# STM32MP23_CM33 register map
File version: 1.2
CPU: CM33 r0p1, little endian, MPU, FPU, vendor SysTick, 8 interrupt priority bits
Registers are 32-bit, read-write, reset 0x0 unless marked. A register's access mark holds for its fields unless they carry their own. Offsets are from the block's base; [hi:lo] are bit positions; {n}, {i} and the like mark numbered series; 'fields as' and 'values as' point back to an identical list.

## DSI (part 2 of 2) — DSI address block description
Base 0x48000000
Same registers: DSI_S 0x58000000
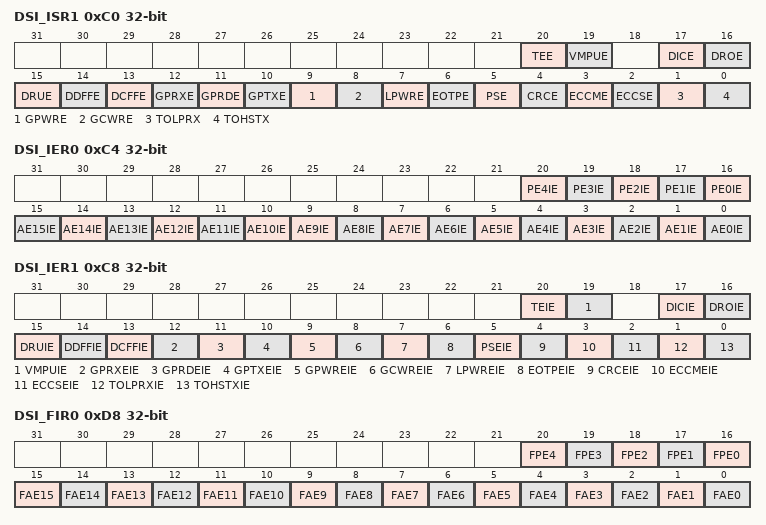
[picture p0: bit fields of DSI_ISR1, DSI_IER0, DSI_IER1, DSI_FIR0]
0xC0 DSI_ISR1 ro — DSI Host interrupt and status register 1
  [20] TEE — Tear effect error Indicates that tear_request has occurred, but tear effect is not active in DSI host and device.
  [19] VMPUE — Video mode underflow error Indicates that an underflow has occurred when reading payload to build DSI packet for video mode.
  [17] DICE — DBI illegal command error Indicates that an attempt to write an illegal command on the DBI interface is made and the controller is blocked by transmission.
  [16] DROE — DBI read overflow error Indicates that during a DBI read back packet, the payload FIFO becomes full and the received data is corrupted.
  [15] DRUE — DCS read underflow error Indicates that during a DCS read data, the payload FIFO goes empty and the data sent to the interface is corrupted.
  [14] DDFFE — DBI data FIFO full error Indicates that the system tried to write the payload data through the DBI interface and the FIFO is full. Therefore, the command is not written.
  [13] DCFFE — DBI command FIFO full error Indicates that the system tried to write a command through the DBI but the command FIFO is full. Therefore, the command is not written.
  [12] GPRXE — Generic payload receive error Indicates that during a generic interface packet read back, the payload FIFO becomes full and the received data is corrupted.
  [11] GPRDE — Generic payload read error Indicates that during a DCS read data, the payload FIFO becomes empty and the data sent to the interface is corrupted.
  [10] GPTXE — Generic payload transmit error Indicates that during a generic interface packet build, the payload FIFO becomes empty and corrupt data is sent.
  [9] GPWRE — Generic payload write error Indicates that the system tried to write a payload data through the generic interface and the FIFO is full. Therefore, the payload is not written.
  [8] GCWRE — Generic command write error Indicates that the system tried to write a command through the generic interface and the FIFO is full. Therefore, the command is not written.
  [7] LPWRE — LTDC payload write error Indicates that during a DPI pixel line storage, the payload FIFO becomes full and the data stored is corrupted.
  [6] EOTPE — EoTp error Indicates that the EoTp packet is not received at the end of the incoming peripheral transmission.
  [5] PSE — Packet size error Indicates that the packet size error is detected during the packet reception.
  [4] CRCE — CRC error Indicates that the CRC error is detected in the received packet payload.
  [3] ECCME — ECC multi-bit error Indicates that the ECC multiple error is detected in a received packet.
  [2] ECCSE — ECC single-bit error Indicates that the ECC single error is detected and corrected in a received packet.
  [1] TOLPRX — Timeout low-power reception Indicates that the low-power reception timeout counter reached the end and contention is detected.
  [0] TOHSTX — Timeout high-speed transmission Indicates that the high-speed transmission timeout counter reached the end and contention is detected.
0xC4 DSI_IER0 — DSI Host interrupt enable register 0
  [20] PE4IE — PHY error 4 interrupt enable Enables the interrupt generation on PHY error 4.
    0=Interrupt on PHY error 4 disabled; 1=Interrupt on PHY error 4 enabled
  [19] PE3IE — PHY error 3 interrupt enable Enables the interrupt generation on PHY error 4.
    0=Interrupt on PHY error 3 disabled; 1=Interrupt on PHY error 3 enabled
  [18] PE2IE — PHY error 2 interrupt enable Enables the interrupt generation on PHY error 2.
    0=Interrupt on PHY error 2 disabled; 1=Interrupt on PHY error 2 enabled
  [17] PE1IE — PHY error 1 interrupt enable Enables the interrupt generation on PHY error 1.
    0=Interrupt on PHY error 1 disabled; 1=Interrupt on PHY error 1 enabled
  [16] PE0IE — PHY error 0 interrupt enable Enables the interrupt generation on PHY error 0.
    0=Interrupt on PHY error 0 disabled; 1=Interrupt on PHY error 0 enabled
  [n] AE{n}IE (n=11..15) — Acknowledge error {n} interrupt enable Enables the interrupt generation on acknowledge error {n}.
    0=Interrupt on acknowledge error {n} disabled; 1=Interrupt on acknowledge error {n} enabled
  [10] AE10IE — Acknowledge error 10 interrupt enable Enables the interrupt generation on acknowledge error 10.
    0=Interrupt on acknowledge error 10 disabled; 1=Interrupt on acknowledge error 10 enable
  [n] AE{n}IE (n=0..9) — Acknowledge error {n} interrupt enable Enables the interrupt generation on acknowledge error {n}.
    values as AE11IE
0xC8 DSI_IER1 — DSI Host interrupt enable register 1
  [all] fields
    0=Interrupt disabled; 1=Interrupt enabled
  [20] TEIE ro — Tear effect error interrupt enable Enables the interrupt generation on tear effect error.
  [19] VMPUIE ro — Video mode underflow error interrupt enable Enables the interrupt generation on video mode underflow error.
  [17] DICIE ro — DBI illegal command error interrupt enable Enables the interrupt generation on DBI illegal command error.
  [16] DROIE ro — DBI read overflow error interrupt enable Enables the interrupt generation on DBI read overflow error.
  [15] DRUIE ro — DCS read underflow error interrupt enable Enables the interrupt generation on DCS read underflow error.
  [14] DDFFIE ro — DBI data FIFO full error interrupt enable Enables the interrupt generation on DBI data FIFO full error.
  [13] DCFFIE ro — DBI command FIFO full error interrupt enable Enables the interrupt generation on DBI command FIFO full error.
  [12] GPRXEIE — Generic payload receive error interrupt enable Enables the interrupt generation on generic payload receive error.
  [11] GPRDEIE — Generic payload read error interrupt enable Enables the interrupt generation on generic payload read error.
  [10] GPTXEIE — Generic payload transmit error interrupt enable Enables the interrupt generation on generic payload transmit error.
  [9] GPWREIE — Generic payload write error interrupt enable Enables the interrupt generation on generic payload write error.
  [8] GCWREIE — Generic command write error interrupt enable Enables the interrupt generation on generic command write error.
  [7] LPWREIE — LTDC payload write error interrupt enable Enables the interrupt generation on LTDC payload write error.
  [6] EOTPEIE — EoTp error interrupt enable Enables the interrupt generation on EoTp error.
  [5] PSEIE — Packet size error interrupt enable Enables the interrupt generation on packet size error.
  [4] CRCEIE — CRC error interrupt enable Enables the interrupt generation on CRC error.
  [3] ECCMEIE — ECC multi-bit error interrupt enable Enables the interrupt generation on ECC multi-bit error.
  [2] ECCSEIE — ECC single-bit error interrupt enable Enables the interrupt generation on ECC single-bit error.
  [1] TOLPRXIE — Timeout low-power reception interrupt enable Enables the interrupt generation on timeout low-power reception.
  [0] TOHSTXIE — Timeout high-speed transmission interrupt enable Enables the interrupt generation on timeout high-speed transmission.
0xCC DSI_PCCR — DSI Host PHY calibration control register
  [0] CSEN — Calibration start for the high-speed skew of the D-PHY:
    0=Calibration disabled; 1=Calibration enabled
0xD8 DSI_FIR0 wo — DSI Host force interrupt register 0
  [n+16] FPE{n} (n=0..4) — Force PHY error {n} Writing 1 to this bit forces a PHY error {n}.
  [n] FAE{n} (n=0..15) — Force acknowledge error {n} Writing 1 to this bit forces an acknowledge error {n}.
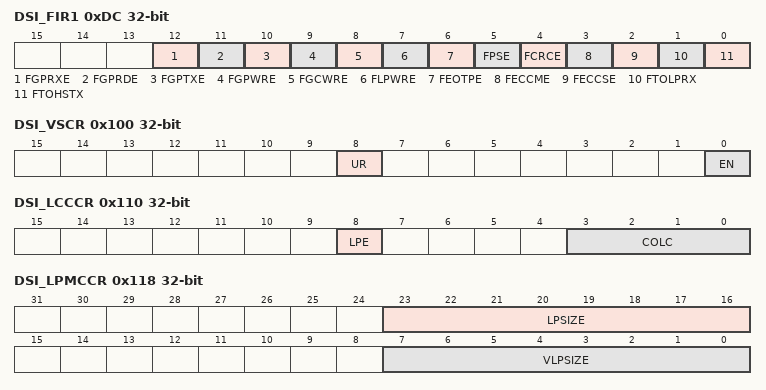
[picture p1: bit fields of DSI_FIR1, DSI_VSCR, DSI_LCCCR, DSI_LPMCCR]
0xDC DSI_FIR1 wo — DSI Host force interrupt register 1
  [12] FGPRXE — Force generic payload receive error Writing 1 to this bit forces a generic payload receive error.
  [11] FGPRDE — Force generic payload read error Writing 1 to this bit forces a generic payload read error.
  [10] FGPTXE — Force generic payload transmit error Writing 1 to this bit forces a generic payload transmit error.
  [9] FGPWRE — Force generic payload write error Writing 1 to this bit forces a generic payload write error.
  [8] FGCWRE — Force generic command write error Writing 1 to this bit forces a generic command write error.
  [7] FLPWRE — Force LTDC payload write error Writing 1 to this bit forces a LTDC payload write error.
  [6] FEOTPE — Force EoTp error Writing 1 to this bit forces a EoTp error.
  [5] FPSE — Force packet size error Writing 1 to this bit forces a packet size error.
  [4] FCRCE — Force CRC error Writing 1 to this bit forces a CRC error.
  [3] FECCME — Force ECC multi-bit error Writing 1 to this bit forces a ECC multi-bit error.
  [2] FECCSE — Force ECC single-bit error Writing 1 to this bit forces a ECC single-bit error.
  [1] FTOLPRX — Force timeout low-power reception Writing 1 to this bit forces a timeout low-power reception.
  [0] FTOHSTX — Force timeout high-speed transmission Writing 1 to this bit forces a timeout high-speed transmission.
0xF4 DSI_DLTRCR — DSI Host data lane timer read configuration register
  [14:0] MRD_TIME — Maximum read time This field configures the maximum time required to perform a read command in lane byte clock cycles. This register can only be modified when no read command is in progress.
0x100 DSI_VSCR — DSI Host video shadow control register
  [8] UR — Update register When set to 1, the LTDC registers are copied to the auxiliary registers. After copying, this bit is auto cleared.
    0=No update requested; 1=Register update requested
  [0] EN — Enable When set to 1, DSI Host LTDC interface receives the active configuration from the auxiliary registers. When this bit is set along with the UR bit, the auxiliary registers are automatically updated.
    0=Register update is disabled; 1=Register update is enabled
0x10C DSI_LCVCIDR — DSI Host LTDC current VCID register
  [1:0] VCID — Virtual channel ID This field returns the virtual channel ID for the LTDC interface.
0x110 DSI_LCCCR ro — DSI Host LTDC current color coding register
  [8] LPE — Loosely packed enable This bit returns the current state of the loosely packed variant to 18-bit configurations.
    0=Loosely packed variant disabled; 1=Loosely packed variant enabled
  [3:0] COLC — Color coding This field returns the current LTDC interface color coding. If LTDC interface in command mode is chosen and currently works in the command mode (CMDM = 1), then 0110-1111: 24-bit
    0=16-bit configuration 1; 1=16-bit configuration 2; 2=16-bit configuration 3; 3=18-bit configuration 1; 4=18-bit configuration 2; 5=24-bit
0x118 DSI_LPMCCR ro — DSI Host low-power mode current configuration register
  [23:16] LPSIZE — Largest packet size This field is returns the current size, in bytes, of the largest packet that can fit in a line during VSA, VBP and VFP regions, for the transmission of commands in low-power mode.
  [7:0] VLPSIZE — VACT largest packet size This field returns the current size, in bytes, of the largest packet that can fit in a line during VACT regions, for the transmission of commands in low-power mode.
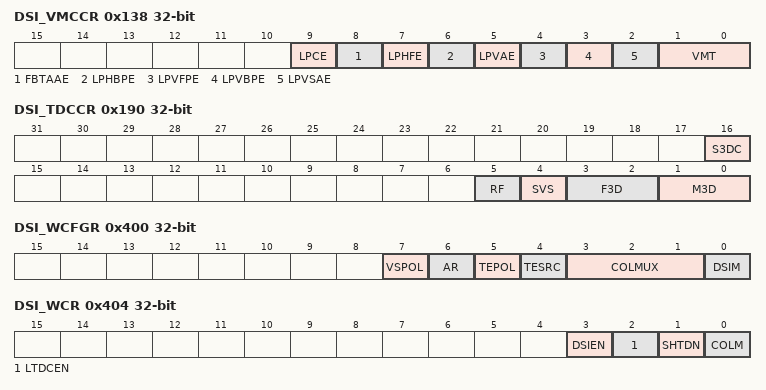
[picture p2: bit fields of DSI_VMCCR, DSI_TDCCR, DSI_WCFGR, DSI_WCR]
0x138 DSI_VMCCR ro — DSI Host video mode current configuration register
  [9] LPCE — Low-power command enable This bit returns the current command transmission state in low-power mode.
    0=Command transmission in low-power mode is disabled; 1=Command transmission in low-power mode is enabled
  [8] FBTAAE — Frame BTA acknowledge enable This bit returns the current state of request for an acknowledge response at the end of a frame.
    0=Acknowledge response at the end of a frame is disabled; 1=Acknowledge response at the end of a frame is enabled
  [7] LPHFE — Low-power horizontal front-porch enable This bit returns the current state of return to low-power inside the horizontal front-porch (HFP) period when timing allows.
    0=Return to low-power inside the HFP period is disabled; 1=Return to low-power inside the HFP period is enabled
  [6] LPHBPE — Low-power horizontal back-porch enable This bit returns the current state of return to low-power inside the horizontal back-porch (HBP) period when timing allows.
    0=Return to low-power inside the HBP period is disabled; 1=Return to low-power inside the HBP period is enabled
  [5] LPVAE — Low-power vertical active enable This bit returns the current state of return to low-power inside the vertical active (VACT) period when timing allows.
    0=Return to low-power inside the VACT is disabled; 1=Return to low-power inside the VACT is enabled
  [4] LPVFPE — Low-power vertical front-porch enable This bit returns the current state of return to low-power inside the vertical front-porch (VFP) period when timing allows.
    0=Return to low-power inside the VFP is disabled; 1=Return to low-power inside the VFP is enabled
  [3] LPVBPE — Low-power vertical back-porch enable This bit returns the current state of return to low-power inside the vertical back-porch (VBP) period when timing allows.
    0=Return to low-power inside the VBP is disabled; 1=Return to low-power inside the VBP is enabled
  [2] LPVSAE — Low-power vertical sync time enable This bit returns the current state of return to low-power inside the vertical sync time (VSA) period when timing allows.
    0=Return to low-power inside the VSA is disabled; 1=Return to low-power inside the VSA is enabled
  [1:0] VMT — Video mode type This field returns the current video mode transmission type: 1x: Burst mode
    0=Non-burst with sync pulses; 1=Non-burst with sync events
0x13C DSI_VPCCR ro — DSI Host video packet current configuration register
  [13:0] VPSIZE — Video packet size This field returns the number of pixels in a single video packet.
0x140 DSI_VCCCR ro — DSI Host video chunks current configuration register
  [12:0] NUMC — Number of chunks This field returns the number of chunks transmitted during a line period.
0x144 DSI_VNPCCR ro — DSI Host video null packet current configuration register
  [12:0] NPSIZE — Null packet size This field returns the number of bytes inside a null packet.
0x148 DSI_VHSACCR ro — DSI Host video HSA current configuration register
  [11:0] HSA — Horizontal synchronism active duration This fields returns the horizontal synchronism active period in lane byte clock cycles.
0x14C DSI_VHBPCCR ro — DSI Host video HBP current configuration register
  [11:0] HBP — Horizontal back-porch duration This field returns the horizontal back-porch period in lane byte clock cycles.
0x150 DSI_VLCCR ro — DSI Host video line current configuration register
  [14:0] HLINE — Horizontal line duration This field returns the current total of the horizontal line period (HSA+HBP+HACT+HFP) counted in lane byte clock cycles.
0x154 DSI_VVSACCR ro — DSI Host video VSA current configuration register
  [9:0] VSA — Vertical synchronism active duration This field returns the current vertical synchronism active period measured in number of horizontal lines.
0x158 DSI_VVBPCCR ro — DSI Host video VBP current configuration register
  [9:0] VBP — Vertical back-porch duration This field returns the current vertical back-porch period measured in number of horizontal lines.
0x15C DSI_VVFPCCR ro — DSI Host video VFP current configuration register
  [9:0] VFP — Vertical front-porch duration This field returns the current vertical front-porch period measured in number of horizontal lines.
0x160 DSI_VVACCR ro — DSI Host video VA current configuration register
  [13:0] VA — Vertical active duration This field returns the current vertical active period measured in number of horizontal lines.
0x190 DSI_TDCCR ro — DSI Host 3D current configuration register
  [16] S3DC — Send 3D control This bit returns the current state of 3D control Sending: when set, causes the next VSS packet to include 3D control payload in every VSS packet.
  [5] RF — Right first This bit returns the left or right order.
    0=Left eye data is sent first, and then the right eye data is sent; 1=Right eye data is sent first, and then the left eye data is sent
  [4] SVS — Second VSYNC This bit returns whether there is a second VSYNC pulse between left and right images, when 3D Image format is frame-based.
    0=No sync pulses between left and right data; 1=Sync pulse (HSYNC, VSYNC, blanking) between left and right data
  [3:2] F3D — 3D format This field returns the 3D image format.
    0=Line (alternating lines of left and right data); 1=Frame (alternating frames of left and right data); 2=Pixel (alternating pixels of left and right data)
  [1:0] M3D — 3D mode This field returns the 3D mode on/off and display orientation.
    0=3D mode off (2D mode on); 1=3D mode on, portrait orientation; 2=3D mode on, landscape orientation
0x400 DSI_WCFGR — DSI Wrapper configuration register
  [7] VSPOL — VSync polarity This bit selects the VSync edge on which the LTDC is halted. This bit can be changed only when DSI is stopped (DSI_WCR.DSIEN = 0 and DSI_CR.EN=0).
    0=LTDC halted on a falling edge; 1=LTDC halted on a rising edge
  [6] AR — Automatic refresh This bit selects the refresh mode in DBI mode. This bit can be changed only when DSI Host is stopped (DSI_CR.EN = 0).
    0=Automatic refresh mode disabled; 1=Automatic refresh mode enabled
  [5] TEPOL — TE polarity This bit selects the polarity of the external pin tearing effect (TE) source. This bit can be changed only when DSI Host is stopped (DSI_CR.EN = 0).
    0=Rising edge; 1=Falling edge
  [4] TESRC — TE source This bit selects the tearing effect (TE) source. This bit can be changed only when DSI Host is stopped (DSI_CR.EN = 0).
    0=DSI Link; 1=External pin
  [3:1] COLMUX — Color multiplexing This bit selects the color multiplexing used by DSI Host. This field can be changed only when DSI is stopped (DSI_WCR.DSIEN = 0 and DSI_CR.EN=0).
    values as DSI_LCCCR.COLC
  [0] DSIM — DSI mode This bit selects the mode for the video transmission. This bit can be changed only when DSI Host is stopped (DSI_CR.EN = 0).
    0=Video mode; 1=Adapted command mode
0x404 DSI_WCR — DSI Wrapper control register
  [3] DSIEN — DSI enable Enables the DSI Wrapper.
    0=DSI disabled; 1=DSI enabled
  [2] LTDCEN — LTDC enable Enables the LTDC for a frame transfer in adapted command mode.
    0=LTDC disabled; 1=LTDC enabled
  [1] SHTDN — Shutdown This bit controls the display shutdown in video mode.
    0=Display ON; 1=Display OFF. The DSI PHY is set in power-down, which allows to modify its static settings.
  [0] COLM — Color mode This bit controls the display color mode in video mode.
    0=Full color mode; 1=Eight color mode
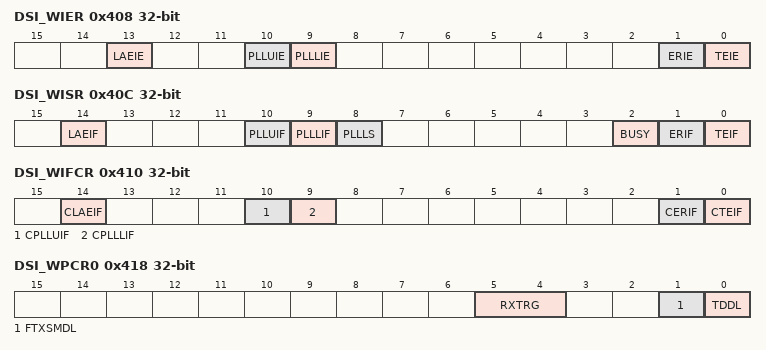
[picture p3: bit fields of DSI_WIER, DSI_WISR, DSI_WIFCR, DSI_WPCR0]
0x408 DSI_WIER — DSI Wrapper interrupt enable register
  [13] LAEIE — LCD APB error interrupt flag Enables the LCD APB error interrupt.
    0=APB error interrupt disabled; 1=APB error interrupt enabled
  [10] PLLUIE — PLL unlock interrupt enable Enables the PLL unlock interrupt.
    0=PLL unlock interrupt disabled; 1=PLL unlock interrupt enabled
  [9] PLLLIE — PLL lock interrupt enable Enables the PLL lock interrupt.
    0=PLL lock interrupt disabled; 1=PLL lock interrupt enabled
  [1] ERIE — End of refresh interrupt enable Enables the end of refresh interrupt.
    0=End of refresh interrupt disabled; 1=End of refresh interrupt enabled
  [0] TEIE — Tearing effect interrupt enable Enables the tearing effect interrupt.
    0=Tearing effect interrupt disabled; 1=Tearing effect interrupt enabled
0x40C DSI_WISR — DSI Wrapper interrupt and status register
  [14] LAEIF — LCD APB error interrupt flag This bit is set when an APB error occurs
    0=No APB error occurred; 1=APB error unlock event occurred
  [10] PLLUIF ro — PLL unlock interrupt flag This bit is set when the PLL becomes unlocked.
    0=No PLL unlock event occurred; 1=PLL unlock event occurred
  [9] PLLLIF ro — PLL lock interrupt flag This bit is set when the PLL becomes locked.
    0=No PLL lock event occurred; 1=PLL lock event occurred
  [8] PLLLS ro — PLL lock status This bit is set when the PLL is locked and cleared when it is unlocked.
    0=PLL is unlocked; 1=PLL is locked
  [2] BUSY ro — Busy flag This bit is set when the transfer of a frame in adapted command mode is ongoing.
    0=No transfer on going; 1=Transfer on going
  [1] ERIF ro — End of refresh interrupt flag This bit is set when the transfer of a frame in adapted command mode is finished.
    0=No end of refresh event occurred; 1=End of refresh event occurred
  [0] TEIF ro — Tearing effect interrupt flag This bit is set when a tearing effect event occurs.
    0=No tearing effect event occurred; 1=Tearing effect event occurred
0x410 DSI_WIFCR wo — DSI Wrapper interrupt flag clear register
  [14] CLAEIF — LCD APB error interrupt flag Writing 1 clears the RRIF flag in the DSI_WSR register.
  [10] CPLLUIF — Clear PLL unlock interrupt flag Writing 1 clears the PLLUIF flag in the DSI_WSR register.
  [9] CPLLLIF — Clear PLL lock interrupt flag Writing 1 clears the PLLLIF flag in the DSI_WSR register.
  [1] CERIF — Clear end of refresh interrupt flag Writing 1 clears the ERIF flag in the DSI_WSR register.
  [0] CTEIF — Clear tearing effect interrupt flag Writing 1 clears the TEIF flag in the DSI_WSR register.
0x418 DSI_WPCR0 — DSI Wrapper PHY configuration register 0
  [5:4] RXTRG — Rx trigger escape selection Writing 1 clears the RRIF flag in the DSI_WSR register.
  [1] FTXSMDL — Force to TX stop mode the data lanes This bit forces the data lanes to Tx stop mode. It is used to initialize a lane module in Transmit mode. It causes the lane module to immediately jump to Tx control mode and to begin transmitting a Stop state (LP-11). It can be used to go back in Tx mode after a wrong BTA sequence.
    0=No effect; 1=Forces to Tx stop mode
  [0] TDDL — Turnaround disable data lanes This bit forces the data lanes to remain in Rx mode even if it receives a bus turn around request form the other side.
    0=No effect; 1=Force data lanes in Rx mode after a BusTurnAround
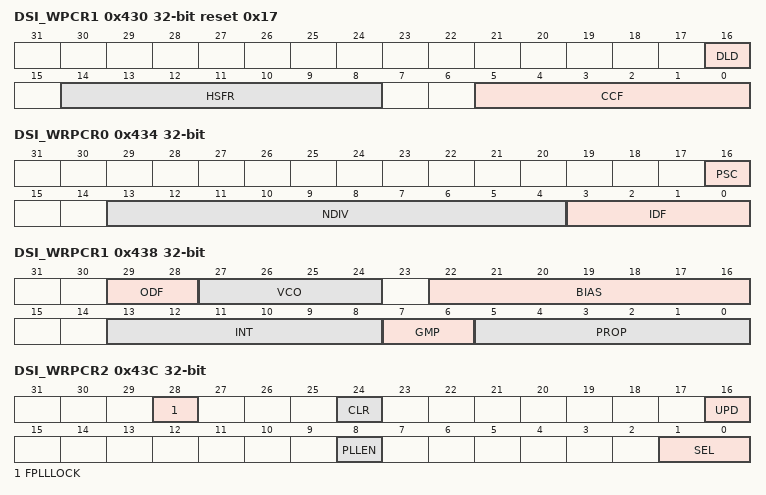
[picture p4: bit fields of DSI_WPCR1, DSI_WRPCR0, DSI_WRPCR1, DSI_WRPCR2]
0x430 DSI_WPCR1 reset 0x17 — DSI Wrapper PHY configuration register 1
  [16] DLD — Data lanes 0 direction:
    0=Rx; 1=Tx
  [14:8] HSFR — High speed frequency range in Tx mode. The values are given in Table518, This field must be set when the DPHY TX is in power-down, and must not change during operation.
  [5:0] CCF — Configuration clock frequency: Indicates the frequency of the clock used to configure the PHY and the PLL. It is computed as Value = Round((Frequency (in MHz) - 17) * 4). As an example, a 25.75 MHz reference clock requires SCCFG = (25.75 - 17) * 4 = 35.
0x434 DSI_WRPCR0 — DSI Wrapper regulator and PLL configuration register 0
  [16] PSC — PLL shadow control Defines who controls the PLL frequency and regulator settings:
    0=PHY test registers control the PLL; 1=Wrapper controls the PLL (via registers DSI_WRPCR0/1/2). It is recommended to use the wrapper control, as the PHY test registers are reserved.
  [13:4] NDIV — PLL InLoop division ratio: NDIV is active if DSI_WPCR0.PSC = 1’b0. NDIV valid range is 10’h03E to 10’h26F (others are reserved). The effective InLoop division ratio is equal to NDIV+2, thus from (d64 to d625).
  [3:0] IDF — PLL input division ratio: IDF is active if DSI_WPCR0.PSC = 1’b0, valid range is 4’h0 to 4’hF. The effective input division is equal to IDF + 1, thus from (d1 to d16).
0x438 DSI_WRPCR1 — DSI Wrapper regulator and PLL configuration register 1
  [29:28] ODF — Output division factor This is the factor that divides the VCO, to provide the final output signal. ODF is active if DSI_WPCR0.PSC = 1’b0.
    0=ratio 1/2 (cannot be divided by 1); 1=ratio 1/2
  [27:24] VCO — VCO operating range VCO is active if DSI_WPCR0.PSC = 1’b0. For VCO valid range see Table 517.
  [22:16] BIAS — Charge pump bias BIAS is active if DSI_WPCR0.PSC = 1’b0. For BIAS valid range see Table 517.
  [13:8] INT — Integral of charge pump INT is active if DSI_WPCR0.PSC = 1’b0. For INT valid range see Table 517.
  [7:6] GMP — Loop filter resistance GMP is active if DSI_WPCR0.PSC = 1’b0. For GMP valid range see Table 517.
  [5:0] PROP — Proportional charge pump PROP is active if DSI_WPCR0.PSC = 1’b0. For PROP valid range see Table 517.
0x43C DSI_WRPCR2 — DSI Wrapper regulator and PLL configuration register 2
  [28] FPLLLOCK — Force PLL lock signal Writing 1 forces the PLL lock signal to high value.
    0=No effect; 1=Forces the PLL lock signal to high value
  [24] CLR — Clears the PLL shadow registers to their reset values Writing 1 triggers a clear of the PLL shadow register to their reset values.
    0=No effect; 1=Clears the PLL shadow registers (field must be set, then reset)
  [16] UPD — Update (copies) the PLL shadow registers to the effective PLL registers Writing 1 triggers a copy of the PLL configured fields to the effective fields. The update must occur at least 10 cycles after the start of the reference clock.
    0=No effect; 1=Copies to the shadow registers (field must be set, then reset)
  [8] PLLEN — PLL enable Enables the D-PHY PLL:
    0=PLL disabled; 1=PLL enabled
  [1:0] SEL — Output selection for PLL Clock:
    0=Clock stopped; 1=Clock with four phases output by the PLL
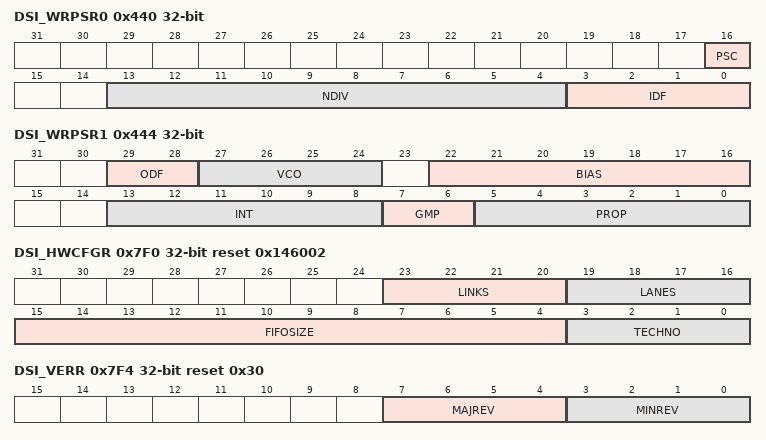
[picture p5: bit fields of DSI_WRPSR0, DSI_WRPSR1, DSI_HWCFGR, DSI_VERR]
0x440 DSI_WRPSR0 ro — DSI Wrapper regulator and PLL status register 0
  [16] PSC — PLL shadow control Defines who controls the PLL frequency and regulator settings:
    0=PHY Test Registers control the PLL; 1=Wrapper controls the PLL (via registers DSI_WRPCR0/1/2)
  [13:4] NDIV — Shadow value of PLL InLoop division ratio NDIV is active if DSI_WPCR0.PSC = 1’b0, its valid range is 10’h03E to 10’h26F (others are reserved). The effective InLoop division ratio is equal to NDIV + 2, thus from (d64 to d625)
  [3:0] IDF — Shadow value of PLL input division ratio IDF is active if DSI_WPCR0.PSC = 1’b0, its valid range is 4’h0 to 4’hF. The effective input division is equal to NDIV+1, thus from (d1 to d16)
0x444 DSI_WRPSR1 — DSI Wrapper regulator and PLL status register 1
  [29:28] ODF — Output division factor Factor that divides the VCO, to provide the final output signal, it is active if DSI_WPCR0.PSC = 1’b0.
    0=ratio 1/1; 1=ratio 1/2
  [27:24] VCO — VCO operating range VCO is active if DSI_WPCR0.PSC = 1’b0. VCO valid range provided by a table.
  [22:16] BIAS — Charge pump bias BIAS is active if DSI_WPCR0.PSC = 1’b0. BIAS valid range is provided by a table.
  [13:8] INT — Charge pump integral INT is active if DSI_WPCR0.PSC = 1’b0. INT valid range is provided by a table.
  [7:6] GMP — Charge pump integral GMP is active if DSI_WPCR0.PSC = 1’b0. GMP valid range is provided by a table.
  [5:0] PROP — Proportional charge pump PROP is active if DSI_WPCR0.PSC = 1’b0. PROP valid range is provided by a table.
0x480 DSI_WCRB wo — DSI Wrapper control register bis
  [2] LTDCEN — LTDC enable Enables the LTDC for a frame transfer in adapted command mode
    0=LTDC is disabled; 1=LTDC is enabled
0x7F0 DSI_HWCFGR ro reset 0x146002 — DSI hardware configuration register
  [23:20] LINKS — Amount of DSI PHY links
    0=Information is not provided; 1=One DSI link is implemented; 2=Two DSI links are implemented
  [19:16] LANES — Amount of DSI DataLanes per Link (excluding the ClockLane)
    0=Information is not provided; 1=One DSI DataLane is implemented; 2=Two DSI DataLanes are implemented; 4=Four DSI DataLanes are implemented
  [15:4] FIFOSIZE — FIFO size This field returns size of the payload FIFO.
  [3:0] TECHNO — Technology This field returns the technology used
    0=TECHNO information is not provided; 1=C40 / M40 PHY; 2=16FF Synopsys PHY
0x7F4 DSI_VERR ro reset 0x30 — DSI version register
  [7:4] MAJREV — Major revision This field returns the major revision of the DSI Host.
  [3:0] MINREV — Minor revision This field returns the minor revision of the DSI Host.
0x7F8 DSI_IPIDR ro reset 0x160081 — DSI identification register
  [31:0] ID — Identification code This field returns the identification code of the DSI Host.
0x7FC DSI_SIDR ro reset 0xA3C5DD02 — DSI size identification register
  [31:0] SID — Size identification code This field returns the size identification of the DSI Host.
